# MWPR1516 register map
Vendor: Freescale Semiconductor, Inc.; Series: Kinetis; File version: 1.6
CPU: CM0PLUS r0p0, little endian, no MPU, no FPU, VTOR, 2 interrupt priority bits
Registers are 8-bit, read-write, reset 0x0 unless marked. A register's access mark holds for its fields unless they carry their own. Offsets are from the block's base; [hi:lo] are bit positions; 'fields as' and 'values as' point back to an identical list.

## PGA — Programmable Gain Amplifier
Base 0x40071000; register names take the prefix PGA_
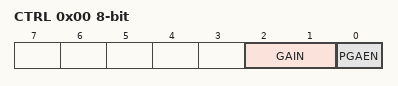
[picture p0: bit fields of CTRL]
0x00 CTRL — Control Register
  [2:1] GAIN — Programmable Gain
    0=The gain is 8; 1=The gain is 10; 2=The gain is 15; 3=The gain is 20
  [0] PGAEN — Programmable Gain Amplifier Enable
    0=Disables the programmable amplifier; 1=Enables the programmable amplifier

## ACMP0 — Analog comparator
Base 0x40073000; register names take the prefix ACMP0_
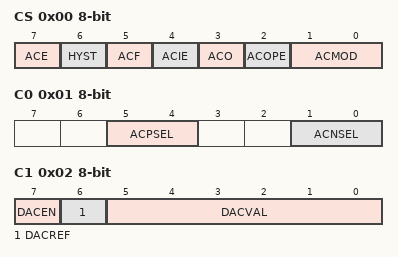
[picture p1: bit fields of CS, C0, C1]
0x00 CS — ACMP Control and Status Register
  [7] ACE — Analog Comparator Enable
    0=The ACMP is disabled; 1=The ACMP is enabled
  [6] HYST — Analog Comparator Hysterisis Selection
    0=20 mV; 1=30 mV
  [5] ACF — ACMP Interrupt Flag Bit
  [4] ACIE — ACMP Interrupt Enable
    0=Disable the ACMP Interrupt; 1=Enable the ACMP Interrupt
  [3] ACO ro — ACMP Output
  [2] ACOPE — ACMP Output Pin Enable
    0=ACMP output cannot be placed onto external pin; 1=ACMP output can be placed onto external pin
  [1:0] ACMOD — ACMP MOD
    0=ACMP interrupt on output falling edge; 1=ACMP interrupt on output rising edge; 2=ACMP interrupt on output falling edge; 3=ACMP interrupt on output falling or rising edge
0x01 C0 — ACMP Control Register 0
  [5:4] ACPSEL — ACMP Positive Input Select
    0=External reference 0; 1=External reference 1; 2=External reference 2; 3=DAC output
  [1:0] ACNSEL — ACMP Negative Input Select
    values as ACPSEL
0x02 C1 — ACMP Control Register 1
  [7] DACEN — DAC Enable
    0=The DAC is disabled; 1=The DAC is enabled
  [6] DACREF — DAC Reference Select
    0=The DAC selects VREFH as the reference; 1=The DAC selects VDDA as the reference
  [5:0] DACVAL — DAC Output Level Selection
0x03 C2 — ACMP Control Register 2
  [2:0] ACIPE — ACMP Input Pin Enable
    0=The corresponding external analog input is not allowed; 1=The corresponding external analog input is allowed

## PMC — Power Management Controller
Base 0x4007D000; register names take the prefix PMC_
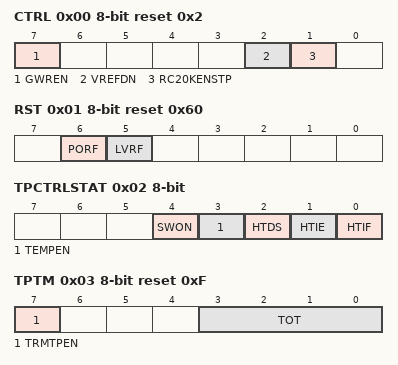
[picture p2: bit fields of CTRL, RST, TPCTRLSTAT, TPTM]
0x00 CTRL reset 0x2 — Control Register
  [7] GWREN — General Write protection Enable
    0=The general write protection is enabled; 1=The general write protection is disabled. Therefore, the related registers are writable.
  [2] VREFDN — VREFH Down
    0=Enables the VREFH regulator; 1=Disables the VREFH regulator
  [1] RC20KENSTP — 20 kHz RC oscillator Enable in Stop mode
    0=Disables 20 kHz RC oscillator in the Stop mode; 1=Enables 20 kHz RC oscillator in the Stop mode
0x01 RST reset 0x60 — Reset Flags Register
  [6] PORF — Power-on Reset Flag
    0=POR does not occur; 1=POR occurs
  [5] LVRF — Low Voltage Reset (LVR) Flag
    0=Low voltage reset does not occur; 1=Low voltage reset occurs
0x02 TPCTRLSTAT — Temperature Control and Status Register
  [4] SWON — Switch On
    0=Selects the temperature sensor output; 1=Selects the bandgap output
  [3] TEMPEN — Temperature sensor Enable
    0=Disables the temperature sensor; 1=Enables the temperature sensor
  [2] HTDS ro — High Temperature Detection Status
    0=Junction temperature is below the alert level; 1=Junction temperature is above the alert level
  [1] HTIE — High Temperature Interrupt Enable
    0=Disables the high temperature interrupt; 1=Enables the high temperature interrupt
  [0] HTIF — High Temperature Interrupt Flag
    0=No change in the HTDS bit; 1=The HTDS bit changes
0x03 TPTM reset 0xF — Temperature Offset Step Trim Register
  [7] TRMTPEN — Temperature offset Trim Enable
    0=The temperature sensor offset is disabled. TOT[3:0] takes no effect.; 1=The temperature sense offset is enabled. TOT[3:0] selects the temperature offset value. See TOT[3:0]Temperature Offset step Trim for more details.
  [3:0] TOT — Temperature Offset step Trim
0x04 RC20KTRM reset 0x1F — RC Oscillator Offset Step Trim Register
  [5:0] OSCOT — RC Oscillator Offset step Trim
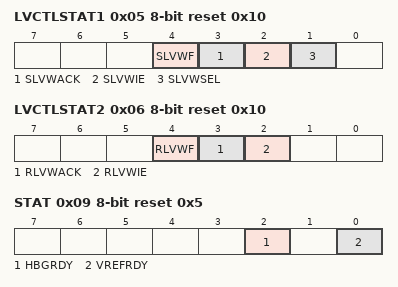
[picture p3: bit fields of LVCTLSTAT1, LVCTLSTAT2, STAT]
0x05 LVCTLSTAT1 reset 0x10 — Low Voltage Control and Status Register 1 (system 5 V)
  [4] SLVWF ro — Low Voltage Warning (LVW) Flag for VDDX
    0=Low voltage warning event is not detected; 1=Low voltage warning event is detected
  [3] SLVWACK wo — Low Voltage Warning Acknowledge
  [2] SLVWIE — Low Voltage Warning Interrupt Enable
    0=Hardware interrupt disabled (use polling); 1=Request a hardware interrupt when SLVWF = 1
  [1] SLVWSEL — Low Voltage Warning Selection
    0=4.2 V LVW threshold selected; 1=3.7 V LVW threshold selected
0x06 LVCTLSTAT2 reset 0x10 — Low Voltage Control and Status Register 2 (VREFH)
  [4] RLVWF ro — Low Voltage Warning Flag for VREFH
    values as LVCTLSTAT1.SLVWF
  [3] RLVWACK wo — Low Voltage Warning Acknowledge
  [2] RLVWIE — Low Voltage Warning Interrupt Enable
    0=Hardware interrupt disabled (use polling); 1=Request a hardware interrupt when RLVWF = 1
0x07 VREFHCFG reset 0x3F — VREFH Configuration Register
  [5:0] T5V — Trim 5 V reference voltage for ADC
0x08 VREFHLVW reset 0x2 — VREFH Low Voltage Warning (LVW) Configuration Register
  [1:0] LVWCFG — VREFH LVW reference voltage Configuration
    0=3.6 V LVW threshold; 1=3.7 V LVW threshold; 2=4.1 V LVW threshold; 3=4.4 V LVW threshold
0x09 STAT ro reset 0x5 — Status Register
  [2] HBGRDY — High-accuracy Bandgap Ready flag
    0=Below 0.8 V, this bit is cleared; 1=Above 1 V, this bit is asserted
  [0] VREFRDY — VREFH Ready flag
    0=Below 3.0 V, this bit is cleared; 1=Above 3.45 V, this bit is asserted

## MCM — Core Platform Miscellaneous Control Module
Base 0xF0003000; register names take the prefix MCM_
0x08 PLASC 16-bit ro reset 0x7 — Crossbar Switch (AXBS) Slave Configuration
  [7:0] ASC — Each bit in the ASC field indicates whether there is a corresponding connection to the crossbar switch's slave input port.
    0=A bus slave connection to AXBS input port n is absent; 1=A bus slave connection to AXBS input port n is present
0x0A PLAMC 16-bit ro reset 0x9 — Crossbar Switch (AXBS) Master Configuration
  [7:0] AMC — Each bit in the AMC field indicates whether there is a corresponding connection to the AXBS master input port.
    0=A bus master connection to AXBS input port n is absent; 1=A bus master connection to AXBS input port n is present
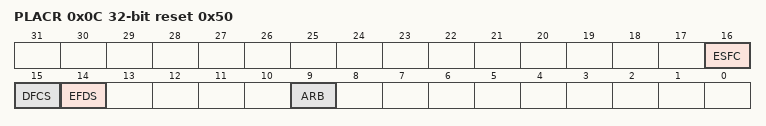
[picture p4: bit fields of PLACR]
0x0C PLACR 32-bit reset 0x50 — Platform Control Register
  [16] ESFC — Enable Stalling Flash Controller
    0=Disable stalling flash controller when flash is busy; 1=Enable stalling flash controller when flash is busy
  [15] DFCS — Disable Flash Controller Speculation
    0=Enable flash controller speculation; 1=Disable flash controller speculation
  [14] EFDS — Enable Flash Data Speculation
    0=Disable flash data speculation; 1=Enable flash data speculation
  [9] ARB — Arbitration select
    0=Fixed-priority arbitration for the crossbar masters; 1=Round-robin arbitration for the crossbar masters
